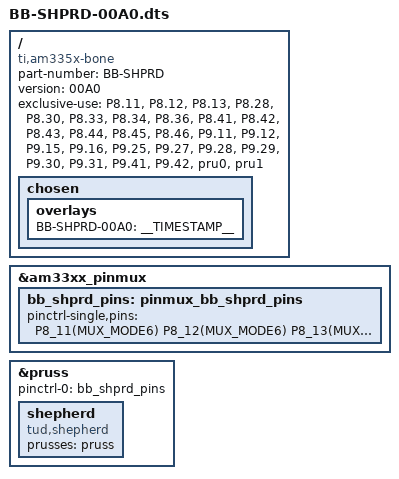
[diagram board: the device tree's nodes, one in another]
/dts-v1/;
/plugin/;
#include "am335x_pinctrl.h"

/*
// future-reference, gpio.h contains: BONE_P8_03, etc
#include <dt-bindings/gpio/gpio.h>
// future-reference, omap.h contains: MUX_MODE#, PULL_UP, INPUT_EN, AM33XX_IOPAD, AM33XX_PADCONF, etc
#include <dt-bindings/pinctrl/omap.h>
*/


/ {
   // note: (older) "ti,beaglebone" types seem to be working as well for v4.19.x-ti, but this is more future-proof
   compatible = "ti,am335x-bone", "ti,am335x-bone-black", "ti,am335x-bone-green";

   part-number = "BB-SHPRD";
   version = "00A0";

   /* This overlay uses the following resources */
   exclusive-use =
        "P8.11", /* DEBUG PIN0 PRU0 */
        "P8.12", /* LED1 PRU0 */
        "P8.13", /* ENABLE HARVESTER */
        "P8.28", /* ADC RST/PDN */
        "P8.30", /* LED2 USER SPACE */
        "P8.33", /* GENERAL PURPOSE LED */
        "P8.34", /* GENERAL PURPOSE BUTTON */
        "P8.36", /* ENABLE LEVEL CONVERTER */
        "P8.41", /* DEBUG PIN0 PRU1 */
        "P8.42", /* DEBUG PIN1 PRU1 */
        "P8.43", /* TARGET GPIO2 */
        "P8.44", /* TARGET GPIO3 */
        "P8.45", /* TARGET GPIO0 */
        "P8.46", /* TARGET GPIO1 */
        "P9.11", /* ENABLE MPPT# */
        "P9.12", /* ENABLE V ANALOG */
        "P9.15", /* SELECT LOAD HOST */
        "P9.16", /* ENABLE V FIXED*/
        "P9.25", /* SPI CS ADC */
        "P9.27", /* SPI MISO */
        "P9.28", /* SPI SCLK */
        "P9.29", /* SELECT LOAD PRU */
        "P9.30", /* SPI MOSI */
        "P9.31", /* SPI CS DAC */
        "P9.41", /* SWDIO */
        "P9.42", /* SWDCLK */

        /* Realtime Units */
        "pru0",
        "pru1";
   /* Check Table 9-60 in am335x TRM */

   /* Helper to show loaded overlays under: /proc/device-tree/chosen/overlays/  */
   /* Note:
        - root-path and "chosen" seem to produce a warning with dtc, internet is not helpful
        - this is the reference solution choosen by: https://github.com/RobertCNelson/bb.org-overlays
   */
   fragment@0 {
      target-path="/";
      __overlay__ {

         chosen {
            overlays {
               BB-SHPRD-00A0 = __TIMESTAMP__;
            };
         };
      };
   };


   fragment@1 {
      target = <&am33xx_pinmux>;
      __overlay__ {
         bb_shprd_pins: pinmux_bb_shprd_pins {
            pinctrl-single,pins = <

            P8_11(MUX_MODE6) /* pr1_pru0_pru_r30_15 */
            P8_12(MUX_MODE6) /* pr1_pru0_pru_r30_14 */
            P8_13(MUX_MODE7) /* gpio0[23] */
            P8_28(MUX_MODE7) /* gpio2[24] */
            P8_30(MUX_MODE7) /* gpio2[25] */
            P8_33(MUX_MODE7) /* gpio0[9] */
            P8_34(MUX_MODE7 | RX_ACTIVE | PULL_UP) /* gpio2[17] */
            P8_36(MUX_MODE7) /* gpio2[16] */
            P8_41(MUX_MODE5) /* pr1_pru1_pru_r30_4 */
            P8_42(MUX_MODE5) /* pr1_pru1_pru_r30_5 */
            P8_43(MUX_MODE6 | RX_ACTIVE) /* pr1_pru1_pru_r31_2 */
            P8_44(MUX_MODE6 | RX_ACTIVE) /* pr1_pru1_pru_r31_3 */
            P8_45(MUX_MODE6 | RX_ACTIVE) /* pr1_pru1_pru_r31_0 */
            P8_46(MUX_MODE6 | RX_ACTIVE) /* pr1_pru1_pru_r31_1 */

            P9_11(MUX_MODE7) /* gpio0[30] */
            P9_12(MUX_MODE7) /* gpio1[28] */
            P9_15(MUX_MODE7) /* gpio1[16] */
            P9_16(MUX_MODE7) /* gpio1[19] */
            P9_25(MUX_MODE5) /* pr1_pru0_pru_r30_7 */
            P9_27(MUX_MODE6 | RX_ACTIVE) /* pr1_pru0_pru_r31_5 */
            P9_28(MUX_MODE5) /* pr1_pru0_pru_r30_3 */
            P9_29(MUX_MODE7 | RX_ACTIVE | PULL_DISABLE) /* gpio3[15], high imp */
            P9_30(MUX_MODE5) /* pr1_pru0_pru_r30_2 */
            P9_31(MUX_MODE5) /* pr1_pru0_pru_r30_0 */
            P9_41B(MUX_MODE7 | RX_ACTIVE) /* gpio3[20] */
            P9_42B(MUX_MODE7) /* gpio3[18] */

            >;
         };
      };
   };

   fragment@2 {
       target = <&pruss>;
       __overlay__ {
           status = "okay";
            pinctrl-names = "default";
            pinctrl-0 = <&bb_shprd_pins>;
            shepherd{
               compatible = "tud,shepherd";
               prusses = <&pruss>;
            };	
       };
   };

};
